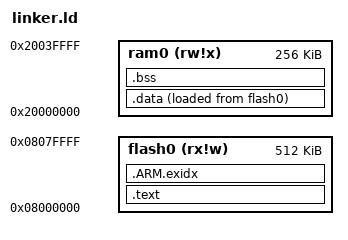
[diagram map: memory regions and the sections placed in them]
/*
 * This file was auto-generated by microzig
 *
 * Target CPU:  ARM Cortex-M7
 * Target Chip: STM32F7x2
 */
/* OUTPUT_FORMAT ("elf32-littlearm", "elf32-bigarm", "elf32-littlearm") */

ENTRY(__start);

MEMORY
{
  flash0 (rx!w) : ORIGIN = 0x08000000, LENGTH = 0x00080000
  ram0   (rw!x) : ORIGIN = 0x20000000, LENGTH = 0x00040000
}


SECTIONS
{
  .text :
  {
     LONG(__stack_end);
     KEEP(*(__flash_start))
     *(.text*)
  } > flash0

  .ARM.exidx : {
      *(.ARM.exidx* .gnu.linkonce.armexidx.*)
  } >flash0

  .data :
  {
     __data_start = .;
     *(.rodata*)
     *(.data*)
     __data_end = .;
  } > ram0 AT> flash0

  .bss (NOLOAD) :
  {
      __bss_start = .;
      *(.bss*)
      __bss_end = .;
  } > ram0

  __data_load_start = LOADADDR(.data);
  __stack_end = (ORIGIN(ram0) + LENGTH(ram0)-8);
}
